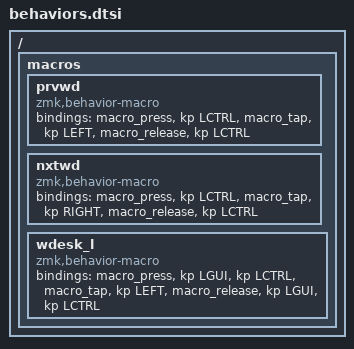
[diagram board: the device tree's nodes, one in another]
/ {
    macros {
        prvwd: prvwd {
            compatible = "zmk,behavior-macro";
            #binding-cells = <0>;
            bindings = <&macro_press &kp LCTRL>
                     , <&macro_tap &kp LEFT>
                     , <&macro_release &kp LCTRL>;
        };
        
        nxtwd: nxtwd {
            compatible = "zmk,behavior-macro";
            #binding-cells = <0>;
            bindings = <&macro_press &kp LCTRL>
                     , <&macro_tap &kp RIGHT>
                     , <&macro_release &kp LCTRL>;
        };

        wdesk_l: wdesk_l {
            compatible = "zmk,behavior-macro";
            #binding-cells = <0>;
            bindings = <&macro_press &kp LGUI &kp LCTRL>
                     , <&macro_tap &kp LEFT>
                     , <&macro_release &kp LGUI &kp LCTRL>;
        };
    };
};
